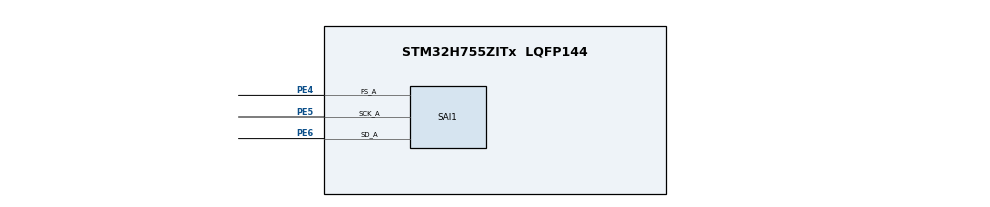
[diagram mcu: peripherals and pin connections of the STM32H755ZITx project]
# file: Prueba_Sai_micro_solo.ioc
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CortexM4.IPs=FATFS_M4\:I,FREERTOS_M4\:I,IWDG2\:I,RCC,WWDG2\:I,DMA,BDMA,MDMA,NVIC2\:I,ETH,USART3,DEBUG,PDM2PCM_M4\:I,PWR,RESMGR_UTILITY,SYS_M4\:I,USB_DEVICE_M4\:I,USB_HOST_M4\:I,CORTEX_M4\:I,GPIO,OPENAMP_M4\:I,VREFBUF,NUCLEO-H755ZI-Q
CortexM7.IPs=FATFS_M7\:I,FREERTOS_M7\:I,IWDG1\:I,RCC\:I,WWDG1\:I,DMA\:I,BDMA\:I,MDMA\:I,NVIC1\:I,ETH\:I,USART3\:I,USB_OTG_FS\:I,SYS\:I,CORTEX_M7\:I,DEBUG\:I,PDM2PCM_M7\:I,PWR\:I,RESMGR_UTILITY\:I,USB_DEVICE_M7\:I,USB_HOST_M7\:I,GPIO\:I,OPENAMP_M7\:I,VREFBUF\:I,NUCLEO-H755ZI-Q\:I,MEMORYMAP\:I,SAI1\:I
Dma.Request0=SAI1_A
Dma.SAI1_A.0.Direction=DMA_PERIPH_TO_MEMORY
Dma.SAI1_A.0.EventEnable=DISABLE
Dma.SAI1_A.0.FIFOMode=DMA_FIFOMODE_DISABLE
Dma.SAI1_A.0.Instance=DMA1_Stream0
Dma.SAI1_A.0.MemDataAlignment=DMA_MDATAALIGN_WORD
Dma.SAI1_A.0.MemInc=DMA_MINC_ENABLE
Dma.SAI1_A.0.Mode=DMA_CIRCULAR
Dma.SAI1_A.0.PeriphDataAlignment=DMA_PDATAALIGN_WORD
Dma.SAI1_A.0.PeriphInc=DMA_PINC_DISABLE
Dma.SAI1_A.0.Polarity=HAL_DMAMUX_REQ_GEN_RISING
Dma.SAI1_A.0.Priority=DMA_PRIORITY_LOW
Dma.SAI1_A.0.RequestNumber=1
Dma.SAI1_A.0.SignalID=NONE
Dma.SAI1_A.0.SyncEnable=DISABLE
Dma.SAI1_A.0.SyncPolarity=HAL_DMAMUX_SYNC_NO_EVENT
Dma.SAI1_A.0.SyncRequestNumber=1
Dma.SAI1_A.0.SyncSignalID=NONE
Mcu.Family=STM32H7
Mcu.Name=STM32H755ZITx
Mcu.Package=LQFP144
NVIC1.DMA1_Stream0_IRQn=true\:0\:0\:false\:false\:true\:false\:true\:true
NVIC1.PriorityGroup=NVIC_PRIORITYGROUP_4
NVIC1.SAI1_IRQn=true\:0\:0\:false\:false\:true\:true\:true\:true
NVIC2.PriorityGroup=NVIC_PRIORITYGROUP_4
PA13\ (JTMS/SWDIO).Mode=Serial_Wire
PA13\ (JTMS/SWDIO).PinAttribute=CortexM7
PA13\ (JTMS/SWDIO).Signal=DEBUG_JTMS-SWDIO
PA14\ (JTCK/SWCLK).Mode=Serial_Wire
PA14\ (JTCK/SWCLK).PinAttribute=CortexM7
PA14\ (JTCK/SWCLK).Signal=DEBUG_JTCK-SWCLK
PA15\ (JTDI).PinAttribute=CortexM7
PA15\ (JTDI).Signal=I2S1_WS
PB0.TagName=LD1
PB14.TagName=LD3
PC13.TagName=BUTTON
PD8.TagName=VCP_RX
PD9.TagName=VCP_TX
PE1.TagName=LD2
PE4.Mode=SAI_A_Master
PE4.PinAttribute=CortexM7
PE4.Signal=SAI1_FS_A
PE5.Mode=SAI_A_Master
PE5.PinAttribute=CortexM7
PE5.Signal=SAI1_SCK_A
PE6.Mode=SAI_A_Master
PE6.PinAttribute=CortexM7
PE6.Signal=SAI1_SD_A
PH0-OSC_IN\ (PH0).Mode=HSE-External-Oscillator
PH0-OSC_IN\ (PH0).PinAttribute=Free
PH0-OSC_IN\ (PH0).Signal=RCC_OSC_IN
PH1-OSC_OUT\ (PH1).Mode=HSE-External-Oscillator
PH1-OSC_OUT\ (PH1).PinAttribute=Free
PH1-OSC_OUT\ (PH1).Signal=RCC_OSC_OUT
ProjectManager.HeapSize=M4-0x200,M7-0x200
ProjectManager.StackSize=M4-0x400,M7-0x400
ProjectManager.TargetToolchain=STM32CubeIDE
RCC.ADCFreq_Value=2759740.25974026
RCC.APB1Freq_Value=100000000
RCC.APB2Freq_Value=100000000
RCC.APB3Freq_Value=100000000
RCC.APB4Freq_Value=100000000
RCC.CortexFreq_Value=400000000
RCC.D1PPRE=RCC_APB3_DIV2
RCC.D2PPRE1=RCC_APB1_DIV2
RCC.D2PPRE2=RCC_APB2_DIV2
RCC.D3PPRE=RCC_APB4_DIV2
RCC.DIVM1=2
RCC.DIVM2=2
RCC.DIVN1=64
RCC.DIVN2=17
RCC.DIVP2=77
RCC.DIVQ1=6
RCC.HCLKFreq_Value=200000000
RCC.HPRE=RCC_HCLK_DIV2
RCC.PLL2FRACN=0
RCC.PLL3FRACN=0
RCC.PLLFRACN=0
RCC.PLLSourceVirtual=RCC_PLLSOURCE_HSE
RCC.SAI1CLockSelection=RCC_SAI1CLKSOURCE_PLL2
RCC.SYSCLKFreq_VALUE=400000000
RCC.SYSCLKSource=RCC_SYSCLKSOURCE_PLLCLK
RCC.SupplySource=PWR_DIRECT_SMPS_SUPPLY
RCC.USBFreq_Value=133333333.33333333
SAI1.ActiveFrameLength-SAI_A_Master=32
SAI1.AudioFrequency-SAI_A_Master=SAI_AUDIO_FREQUENCY_11K
SAI1.AudioMode-SAI_A_Master=SAI_MODEMASTER_RX
SAI1.DataSize-SAI_A_Master=SAI_DATASIZE_24
SAI1.ErrorAudioFreq-SAI_A_Master=-2.22 %
SAI1.FSDefinition-SAI_A_Master=SAI_FS_CHANNEL_IDENTIFICATION
SAI1.FSOffset-SAI_A_Master=SAI_FS_BEFOREFIRSTBIT
SAI1.FirstBitOffset-SAI_A_Master=1
SAI1.FrameLength-SAI_A_Master=64
SAI1.Instance-SAI_A_Master=SAI$Index_Block_A
SAI1.MClockEnable-SAI_A_Master=SAI_MASTERCLOCK_DISABLE
SAI1.RealAudioFreq-SAI_A_Master=10.78 KHz
SAI1.SlotActive-SAI_A_Master=0x00000001
SAI1.SlotNumber-SAI_A_Master=2
SAI1.SlotSize-SAI_A_Master=SAI_SLOTSIZE_32B
SAI1.VirtualMode-SAI_A_Master=VM_MASTER
SAI1.VirtualSlotActive-SAI_A_Master=SAI_SLOT_USERSETTING
SAI1.VirtualSlotActive0-SAI_A_Master=true
VP_MEMORYMAP_VS_MEMORYMAP.Mode=CurAppReg
VP_SYS_M4_VS_Systick.Mode=SysTick
board=NUCLEO-H755ZI-Q

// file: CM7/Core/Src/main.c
/* USER CODE BEGIN Header */
/**
  ******************************************************************************
  * @file           : main.c
  * @brief          : Main program body
  ******************************************************************************
  * @attention
  *
  * Copyright (c) 2026 STMicroelectronics.
  * All rights reserved.
  *
  * This software is licensed under terms that can be found in the LICENSE file
  * in the root directory of this software component.
  * If no LICENSE file comes with this software, it is provided AS-IS.
  *
  ******************************************************************************
  */
/* USER CODE END Header */
#include "main.h"

/* USER CODE BEGIN Includes */
#define AUDIO_BUFF_SIZE 120 //-----------------------------------------------------------------------------Aqui
static volatile uint32_t pAudBuf[AUDIO_BUFF_SIZE];
static volatile uint8_t audio_out_buffer[AUDIO_BUFF_SIZE*3];

static volatile uint8_t first_half_ready  = 0; //Flags
static volatile uint8_t second_half_ready = 0;
volatile int32_t sample;

/* USER CODE END Includes */

/* USER CODE BEGIN PD */

/* DUAL_CORE_BOOT_SYNC_SEQUENCE: Define for dual core boot synchronization    */
/*                             demonstration code based on hardware semaphore */
/* This define is present in both CM7/CM4 projects                            */
/* To comment when developping/debugging on a single core                     */
#define DUAL_CORE_BOOT_SYNC_SEQUENCE

#if defined(DUAL_CORE_BOOT_SYNC_SEQUENCE)
#ifndef HSEM_ID_0
#define HSEM_ID_0 (0U) /* HW semaphore 0*/
#endif
#endif /* DUAL_CORE_BOOT_SYNC_SEQUENCE */

/* USER CODE END PD */

SAI_HandleTypeDef hsai_BlockA1;
DMA_HandleTypeDef hdma_sai1_a;

void SystemClock_Config(void);
static void MX_GPIO_Init(void);
static void MX_DMA_Init(void);
static void MX_SAI1_Init(void);

int main(void)
{

/* USER CODE BEGIN Boot_Mode_Sequence_0 */
#if defined(DUAL_CORE_BOOT_SYNC_SEQUENCE)
  int32_t timeout;
#endif /* DUAL_CORE_BOOT_SYNC_SEQUENCE */
/* USER CODE END Boot_Mode_Sequence_0 */

/* USER CODE BEGIN Boot_Mode_Sequence_1 */
#if defined(DUAL_CORE_BOOT_SYNC_SEQUENCE)
  /* Wait until CPU2 boots and enters in stop mode or timeout*/
  timeout = 0xFFFF;
  while((__HAL_RCC_GET_FLAG(RCC_FLAG_D2CKRDY) != RESET) && (timeout-- > 0));
  if ( timeout < 0 )
  {
  Error_Handler();
  }
#endif /* DUAL_CORE_BOOT_SYNC_SEQUENCE */
/* USER CODE END Boot_Mode_Sequence_1 */
  /* MCU Configuration--------------------------------------------------------*/

  /* Reset of all peripherals, Initializes the Flash interface and the Systick. */
  HAL_Init();

  /* Configure the system clock */
  SystemClock_Config();
/* USER CODE BEGIN Boot_Mode_Sequence_2 */
#if defined(DUAL_CORE_BOOT_SYNC_SEQUENCE)
/* When system initialization is finished, Cortex-M7 will release Cortex-M4 by means of
HSEM notification */
/*HW semaphore Clock enable*/
__HAL_RCC_HSEM_CLK_ENABLE();
/*Take HSEM */
HAL_HSEM_FastTake(HSEM_ID_0);
/*Release HSEM in order to notify the CPU2(CM4)*/
HAL_HSEM_Release(HSEM_ID_0,0);
/* wait until CPU2 wakes up from stop mode */
timeout = 0xFFFF;
while((__HAL_RCC_GET_FLAG(RCC_FLAG_D2CKRDY) == RESET) && (timeout-- > 0));
if ( timeout < 0 )
{
Error_Handler();
}
#endif /* DUAL_CORE_BOOT_SYNC_SEQUENCE */
/* USER CODE END Boot_Mode_Sequence_2 */

  /* USER CODE BEGIN SysInit */
	__HAL_RCC_DMA1_CLK_ENABLE();
  /* USER CODE END SysInit */

  /* Initialize all configured peripherals */
  MX_GPIO_Init();
  MX_DMA_Init();
  MX_SAI1_Init();

  /* Infinite loop */
  /* USER CODE BEGIN WHILE */
 HAL_SAI_Receive_DMA(&hsai_BlockA1, (uint8_t*)pAudBuf, AUDIO_BUFF_SIZE);  //Arranque del DMA
  while (1)
  {

    /* USER CODE END WHILE */
	  if (first_half_ready)
	          {
	              first_half_ready = 0;
	              ProcessAudioBytes(0, AUDIO_BUFF_SIZE / 2);
	          }

	          if (second_half_ready)
	          {
	              second_half_ready = 0;
	              ProcessAudioBytes(AUDIO_BUFF_SIZE / 2, AUDIO_BUFF_SIZE / 2);
	          }
  }
}

void SystemClock_Config(void)
{
  RCC_OscInitTypeDef RCC_OscInitStruct = {0};
  RCC_ClkInitTypeDef RCC_ClkInitStruct = {0};

  /** Supply configuration update enable
  */
  HAL_PWREx_ConfigSupply(PWR_DIRECT_SMPS_SUPPLY);

  /** Configure the main internal regulator output voltage
  */
  __HAL_PWR_VOLTAGESCALING_CONFIG(PWR_REGULATOR_VOLTAGE_SCALE1);

  while(!__HAL_PWR_GET_FLAG(PWR_FLAG_VOSRDY)) {}

  /** Initializes the RCC Oscillators according to the specified parameters
  * in the RCC_OscInitTypeDef structure.
  */
  RCC_OscInitStruct.OscillatorType = RCC_OSCILLATORTYPE_HSE;
  RCC_OscInitStruct.HSEState = RCC_HSE_ON;
  RCC_OscInitStruct.PLL.PLLState = RCC_PLL_ON;
  RCC_OscInitStruct.PLL.PLLSource = RCC_PLLSOURCE_HSE;
  RCC_OscInitStruct.PLL.PLLM = 2;
  RCC_OscInitStruct.PLL.PLLN = 64;
  RCC_OscInitStruct.PLL.PLLP = 2;
  RCC_OscInitStruct.PLL.PLLQ = 6;
  RCC_OscInitStruct.PLL.PLLR = 2;
  RCC_OscInitStruct.PLL.PLLRGE = RCC_PLL1VCIRANGE_3;
  RCC_OscInitStruct.PLL.PLLVCOSEL = RCC_PLL1VCOWIDE;
  RCC_OscInitStruct.PLL.PLLFRACN = 0;
  if (HAL_RCC_OscConfig(&RCC_OscInitStruct) != HAL_OK)
  {
    Error_Handler();
  }

  /** Initializes the CPU, AHB and APB buses clocks
  */
  RCC_ClkInitStruct.ClockType = RCC_CLOCKTYPE_HCLK|RCC_CLOCKTYPE_SYSCLK
                              |RCC_CLOCKTYPE_PCLK1|RCC_CLOCKTYPE_PCLK2
                              |RCC_CLOCKTYPE_D3PCLK1|RCC_CLOCKTYPE_D1PCLK1;
  RCC_ClkInitStruct.SYSCLKSource = RCC_SYSCLKSOURCE_PLLCLK;
  RCC_ClkInitStruct.SYSCLKDivider = RCC_SYSCLK_DIV1;
  RCC_ClkInitStruct.AHBCLKDivider = RCC_HCLK_DIV2;
  RCC_ClkInitStruct.APB3CLKDivider = RCC_APB3_DIV2;
  RCC_ClkInitStruct.APB1CLKDivider = RCC_APB1_DIV2;
  RCC_ClkInitStruct.APB2CLKDivider = RCC_APB2_DIV2;
  RCC_ClkInitStruct.APB4CLKDivider = RCC_APB4_DIV2;

  if (HAL_RCC_ClockConfig(&RCC_ClkInitStruct, FLASH_LATENCY_2) != HAL_OK)
  {
    Error_Handler();
  }
}

static void MX_SAI1_Init(void)
{

  hsai_BlockA1.Instance = SAI1_Block_A;
  hsai_BlockA1.Init.Protocol = SAI_FREE_PROTOCOL;
  hsai_BlockA1.Init.AudioMode = SAI_MODEMASTER_RX;
  hsai_BlockA1.Init.DataSize = SAI_DATASIZE_24;
  hsai_BlockA1.Init.FirstBit = SAI_FIRSTBIT_MSB;
  hsai_BlockA1.Init.ClockStrobing = SAI_CLOCKSTROBING_FALLINGEDGE;
  hsai_BlockA1.Init.Synchro = SAI_ASYNCHRONOUS;
  hsai_BlockA1.Init.OutputDrive = SAI_OUTPUTDRIVE_DISABLE;
  hsai_BlockA1.Init.NoDivider = SAI_MCK_OVERSAMPLING_DISABLE;
  hsai_BlockA1.Init.MckOverSampling = SAI_MCK_OVERSAMPLING_DISABLE;
  hsai_BlockA1.Init.FIFOThreshold = SAI_FIFOTHRESHOLD_EMPTY;
  hsai_BlockA1.Init.AudioFrequency = SAI_AUDIO_FREQUENCY_11K;
  hsai_BlockA1.Init.SynchroExt = SAI_SYNCEXT_DISABLE;
  hsai_BlockA1.Init.MonoStereoMode = SAI_STEREOMODE;
  hsai_BlockA1.Init.CompandingMode = SAI_NOCOMPANDING;
  hsai_BlockA1.Init.PdmInit.Activation = DISABLE;
  hsai_BlockA1.Init.PdmInit.MicPairsNbr = 1;
  hsai_BlockA1.Init.PdmInit.ClockEnable = SAI_PDM_CLOCK1_ENABLE;
  hsai_BlockA1.FrameInit.FrameLength = 64;
  hsai_BlockA1.FrameInit.ActiveFrameLength = 32;
  hsai_BlockA1.FrameInit.FSDefinition = SAI_FS_CHANNEL_IDENTIFICATION;
  hsai_BlockA1.FrameInit.FSPolarity = SAI_FS_ACTIVE_LOW;
  hsai_BlockA1.FrameInit.FSOffset = SAI_FS_BEFOREFIRSTBIT;
  hsai_BlockA1.SlotInit.FirstBitOffset = 1;
  hsai_BlockA1.SlotInit.SlotSize = SAI_SLOTSIZE_32B;
  hsai_BlockA1.SlotInit.SlotNumber = 2;
  hsai_BlockA1.SlotInit.SlotActive = 0x00000001;
  if (HAL_SAI_Init(&hsai_BlockA1) != HAL_OK)
  {
    Error_Handler();
  }

}

static void MX_DMA_Init(void)
{

  /* DMA controller clock enable */
  __HAL_RCC_DMA1_CLK_ENABLE();

  /* DMA interrupt init */
  /* DMA1_Stream0_IRQn interrupt configuration */
  HAL_NVIC_SetPriority(DMA1_Stream0_IRQn, 0, 0);
  HAL_NVIC_EnableIRQ(DMA1_Stream0_IRQn);

}

static void MX_GPIO_Init(void)
{
  GPIO_InitTypeDef GPIO_InitStruct = {0};

  /* GPIO Ports Clock Enable */
  __HAL_RCC_GPIOE_CLK_ENABLE();
  __HAL_RCC_GPIOA_CLK_ENABLE();

  /*Configure GPIO pin : PA15 */
  GPIO_InitStruct.Pin = GPIO_PIN_15;
  GPIO_InitStruct.Mode = GPIO_MODE_AF_PP;
  GPIO_InitStruct.Pull = GPIO_NOPULL;
  GPIO_InitStruct.Speed = GPIO_SPEED_FREQ_LOW;
  GPIO_InitStruct.Alternate = GPIO_AF5_SPI1;
  HAL_GPIO_Init(GPIOA, &GPIO_InitStruct);

}

/* USER CODE BEGIN 4 */
void HAL_SAI_RxHalfCpltCallback(SAI_HandleTypeDef * hsai) {
    for (int i = 0; i < AUDIO_BUFF_SIZE / 2; i++) {
      audio_out_buffer[i * 3 + 2] = (uint8_t)(pAudBuf[i] >> 16);
      audio_out_buffer[i * 3 + 1] = (uint8_t)(pAudBuf[i] >> 8);
      audio_out_buffer[i * 3] = (uint8_t)(pAudBuf[i]);
    }
    first_half_ready = 1;
  }

  void HAL_SAI_RxCpltCallback(SAI_HandleTypeDef * hsai) {
    for (int i = AUDIO_BUFF_SIZE / 2; i < AUDIO_BUFF_SIZE; i++) {
      audio_out_buffer[i * 3 + 2] = (uint8_t)(pAudBuf[i] >> 16);
      audio_out_buffer[i * 3 + 1] = (uint8_t)(pAudBuf[i] >> 8);
      audio_out_buffer[i * 3] = (uint8_t)(pAudBuf[i]);
    }
    second_half_ready = 1;
  }

  void ProcessAudioBytes(uint16_t sample_start, uint16_t sample_count)
  {
      for (uint16_t i = sample_start; i < sample_start + sample_count; i++)
      {
          uint32_t b0 = audio_out_buffer[i * 3];
          uint32_t b1 = audio_out_buffer[i * 3 + 1];
          uint32_t b2 = audio_out_buffer[i * 3 + 2];

          uint32_t raw24 = b0 | (b1 << 8) | (b2 << 16);

          //int32_t sample;
          if (raw24 & 0x00800000)
              sample = (int32_t)(raw24 | 0xFF000000);
          else
              sample = (int32_t)raw24;

          // Aqui envias 'sample' para tu grafica
          // Ejemplo: printf("%ld\r\n", sample);
      }
  }

  //Para usar printf()
int _write(int file,char *ptr,int len){
	int DataIdx;

	for(DataIdx=0;DataIdx<len;DataIdx++){
		ITM_SendChar(*ptr++);
	}
	return len;
}

/* USER CODE END 4 */

void Error_Handler(void)
{
  __disable_irq();
  while (1)
  {
  }
}
